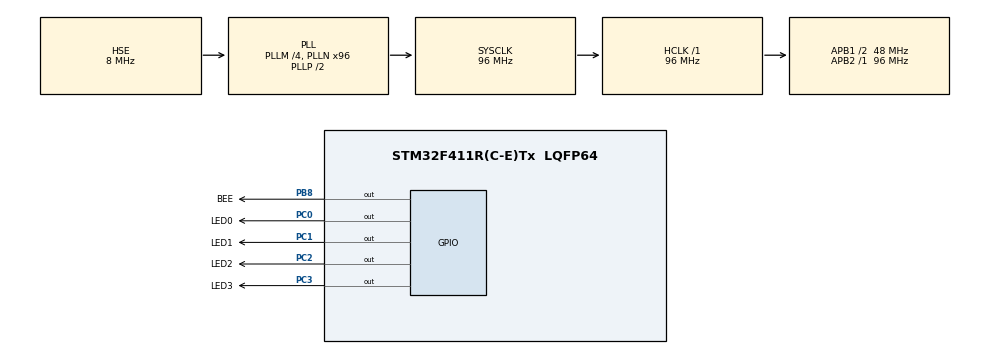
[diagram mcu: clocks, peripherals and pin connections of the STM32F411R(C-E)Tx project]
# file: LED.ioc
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Mcu.Family=STM32F4
Mcu.Name=STM32F411R(C-E)Tx
Mcu.Package=LQFP64
NVIC.PriorityGroup=NVIC_PRIORITYGROUP_4
PB8.GPIO_Label=BEE
PB8.GPIO_PuPd=GPIO_NOPULL
PB8.GPIO_Speed=GPIO_SPEED_FREQ_LOW
PB8.PinState=GPIO_PIN_SET
PB8.Signal=GPIO_Output
PC0.GPIO_Label=LED0
PC0.GPIO_PuPd=GPIO_PULLUP
PC0.GPIO_Speed=GPIO_SPEED_FREQ_HIGH
PC0.PinState=GPIO_PIN_SET
PC0.Signal=GPIO_Output
PC1.GPIO_Label=LED1
PC1.GPIO_ModeDefaultOutputPP=GPIO_MODE_OUTPUT_PP
PC1.GPIO_PuPd=GPIO_PULLUP
PC1.GPIO_Speed=GPIO_SPEED_FREQ_HIGH
PC1.PinState=GPIO_PIN_SET
PC1.Signal=GPIO_Output
PC14-OSC32_IN.Mode=LSE-External-Oscillator
PC14-OSC32_IN.Signal=RCC_OSC32_IN
PC15-OSC32_OUT.Mode=LSE-External-Oscillator
PC15-OSC32_OUT.Signal=RCC_OSC32_OUT
PC2.GPIO_Label=LED2
PC2.GPIO_PuPd=GPIO_PULLUP
PC2.GPIO_Speed=GPIO_SPEED_FREQ_HIGH
PC2.PinState=GPIO_PIN_SET
PC2.Signal=GPIO_Output
PC3.GPIO_Label=LED3
PC3.GPIO_PuPd=GPIO_PULLUP
PC3.GPIO_Speed=GPIO_SPEED_FREQ_HIGH
PC3.PinState=GPIO_PIN_SET
PC3.Signal=GPIO_Output
PH0\ -\ OSC_IN.Mode=HSE-External-Oscillator
PH0\ -\ OSC_IN.Signal=RCC_OSC_IN
PH1\ -\ OSC_OUT.Mode=HSE-External-Oscillator
PH1\ -\ OSC_OUT.Signal=RCC_OSC_OUT
ProjectManager.HeapSize=0x200
ProjectManager.StackSize=0x400
ProjectManager.TargetToolchain=MDK-ARM V5
RCC.48MHZClocksFreq_Value=48000000
RCC.AHBFreq_Value=96000000
RCC.APB1CLKDivider=RCC_HCLK_DIV2
RCC.APB1Freq_Value=48000000
RCC.APB1TimFreq_Value=96000000
RCC.APB2Freq_Value=96000000
RCC.APB2TimFreq_Value=96000000
RCC.CortexFreq_Value=96000000
RCC.HCLKFreq_Value=96000000
RCC.HSE_VALUE=8000000
RCC.HSI_VALUE=16000000
RCC.PLLM=4
RCC.PLLN=96
RCC.PLLSourceVirtual=RCC_PLLSOURCE_HSE
RCC.SYSCLKFreq_VALUE=96000000
RCC.SYSCLKSource=RCC_SYSCLKSOURCE_PLLCLK
RCC.VCOOutputFreq_Value=192000000
board=custom

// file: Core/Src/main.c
/* USER CODE BEGIN Header */
/**
  ******************************************************************************
  * @file           : main.c
  * @brief          : Main program body
  ******************************************************************************
  * @attention
  *
  * <h2><center>&copy; Copyright (c) 2023 STMicroelectronics.
  * All rights reserved.</center></h2>
  *
  * This software component is licensed by ST under BSD 3-Clause license,
  * the "License"; You may not use this file except in compliance with the
  * License. You may obtain a copy of the License at:
  *                        opensource.org/licenses/BSD-3-Clause
  *
  ******************************************************************************
  */
/* USER CODE END Header */
#include "main.h"
#include <bee.h>
#include <led.h>

void SystemClock_Config(void);
static void MX_GPIO_Init(void);

int main(void)
{
  /* USER CODE BEGIN 1 */
    //BEE_ON();
  /* USER CODE END 1 */

  /* MCU Configuration--------------------------------------------------------*/

  /* Reset of all peripherals, Initializes the Flash interface and the Systick. */
  HAL_Init();

  /* Configure the system clock */
  SystemClock_Config();

  /* Initialize all configured peripherals */
  MX_GPIO_Init();
  /* USER CODE BEGIN 2 */
  // LED0_SHIE();
	 //LED1_SHIE();
	 ///LED2_SHIE();
	/// LED3_SHIE();
	 //BEE_BOOT();
	 //BEE_ON();
	// HAL_Delay(100);
	// BEE_ON();
	  LED0_ON();
		HAL_Delay(100);
		LED0_OFF();
		BEE_ON();
		HAL_Delay(100);
		BEE_OFF();
  /* USER CODE END 2 */

  /* Infinite loop */
  while (1)
  {

  }
}

void SystemClock_Config(void)
{
  RCC_OscInitTypeDef RCC_OscInitStruct = {0};
  RCC_ClkInitTypeDef RCC_ClkInitStruct = {0};

  /** Configure the main internal regulator output voltage
  */
  __HAL_RCC_PWR_CLK_ENABLE();
  __HAL_PWR_VOLTAGESCALING_CONFIG(PWR_REGULATOR_VOLTAGE_SCALE1);
  /** Initializes the RCC Oscillators according to the specified parameters
  * in the RCC_OscInitTypeDef structure.
  */
  RCC_OscInitStruct.OscillatorType = RCC_OSCILLATORTYPE_HSE;
  RCC_OscInitStruct.HSEState = RCC_HSE_ON;
  RCC_OscInitStruct.PLL.PLLState = RCC_PLL_ON;
  RCC_OscInitStruct.PLL.PLLSource = RCC_PLLSOURCE_HSE;
  RCC_OscInitStruct.PLL.PLLM = 4;
  RCC_OscInitStruct.PLL.PLLN = 96;
  RCC_OscInitStruct.PLL.PLLP = RCC_PLLP_DIV2;
  RCC_OscInitStruct.PLL.PLLQ = 4;
  if (HAL_RCC_OscConfig(&RCC_OscInitStruct) != HAL_OK)
  {
    Error_Handler();
  }
  /** Initializes the CPU, AHB and APB buses clocks
  */
  RCC_ClkInitStruct.ClockType = RCC_CLOCKTYPE_HCLK|RCC_CLOCKTYPE_SYSCLK
                              |RCC_CLOCKTYPE_PCLK1|RCC_CLOCKTYPE_PCLK2;
  RCC_ClkInitStruct.SYSCLKSource = RCC_SYSCLKSOURCE_PLLCLK;
  RCC_ClkInitStruct.AHBCLKDivider = RCC_SYSCLK_DIV1;
  RCC_ClkInitStruct.APB1CLKDivider = RCC_HCLK_DIV2;
  RCC_ClkInitStruct.APB2CLKDivider = RCC_HCLK_DIV1;

  if (HAL_RCC_ClockConfig(&RCC_ClkInitStruct, FLASH_LATENCY_3) != HAL_OK)
  {
    Error_Handler();
  }
}

static void MX_GPIO_Init(void)
{
  GPIO_InitTypeDef GPIO_InitStruct = {0};

  /* GPIO Ports Clock Enable */
  __HAL_RCC_GPIOC_CLK_ENABLE();
  __HAL_RCC_GPIOH_CLK_ENABLE();
  __HAL_RCC_GPIOB_CLK_ENABLE();

  /*Configure GPIO pin Output Level */
  HAL_GPIO_WritePin(GPIOC, LED0_Pin|LED1_Pin|LED2_Pin|LED3_Pin, GPIO_PIN_SET);

  /*Configure GPIO pin Output Level */
  HAL_GPIO_WritePin(BEE_GPIO_Port, BEE_Pin, GPIO_PIN_SET);

  /*Configure GPIO pins : LED0_Pin LED1_Pin LED2_Pin LED3_Pin */
  GPIO_InitStruct.Pin = LED0_Pin|LED1_Pin|LED2_Pin|LED3_Pin;
  GPIO_InitStruct.Mode = GPIO_MODE_OUTPUT_PP;
  GPIO_InitStruct.Pull = GPIO_PULLUP;
  GPIO_InitStruct.Speed = GPIO_SPEED_FREQ_HIGH;
  HAL_GPIO_Init(GPIOC, &GPIO_InitStruct);

  /*Configure GPIO pin : BEE_Pin */
  GPIO_InitStruct.Pin = BEE_Pin;
  GPIO_InitStruct.Mode = GPIO_MODE_OUTPUT_PP;
  GPIO_InitStruct.Pull = GPIO_NOPULL;
  GPIO_InitStruct.Speed = GPIO_SPEED_FREQ_LOW;
  HAL_GPIO_Init(BEE_GPIO_Port, &GPIO_InitStruct);

}

void Error_Handler(void)
{
  __disable_irq();
  while (1)
  {
  }
}

/************************ (C) COPYRIGHT STMicroelectronics *****END OF FILE****/
